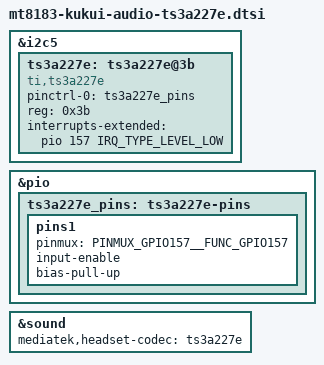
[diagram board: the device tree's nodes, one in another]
// SPDX-License-Identifier: (GPL-2.0 OR MIT)
/*
 * Google Kukui (and derivatives) audio fragment for ts3a227e.
 *
 * Copyright 2019 Google LLC.
 */

&i2c5 {
	ts3a227e: ts3a227e@3b {
		pinctrl-names = "default";
		pinctrl-0 = <&ts3a227e_pins>;
		compatible = "ti,ts3a227e";
		reg = <0x3b>;
		interrupts-extended = <&pio 157 IRQ_TYPE_LEVEL_LOW>;
		status = "okay";
	};
};

&pio {
	ts3a227e_pins: ts3a227e-pins {
		pins1 {
			pinmux = <PINMUX_GPIO157__FUNC_GPIO157>;
			input-enable;
			bias-pull-up;
		};
	};
};

&sound {
	mediatek,headset-codec = <&ts3a227e>;
};
